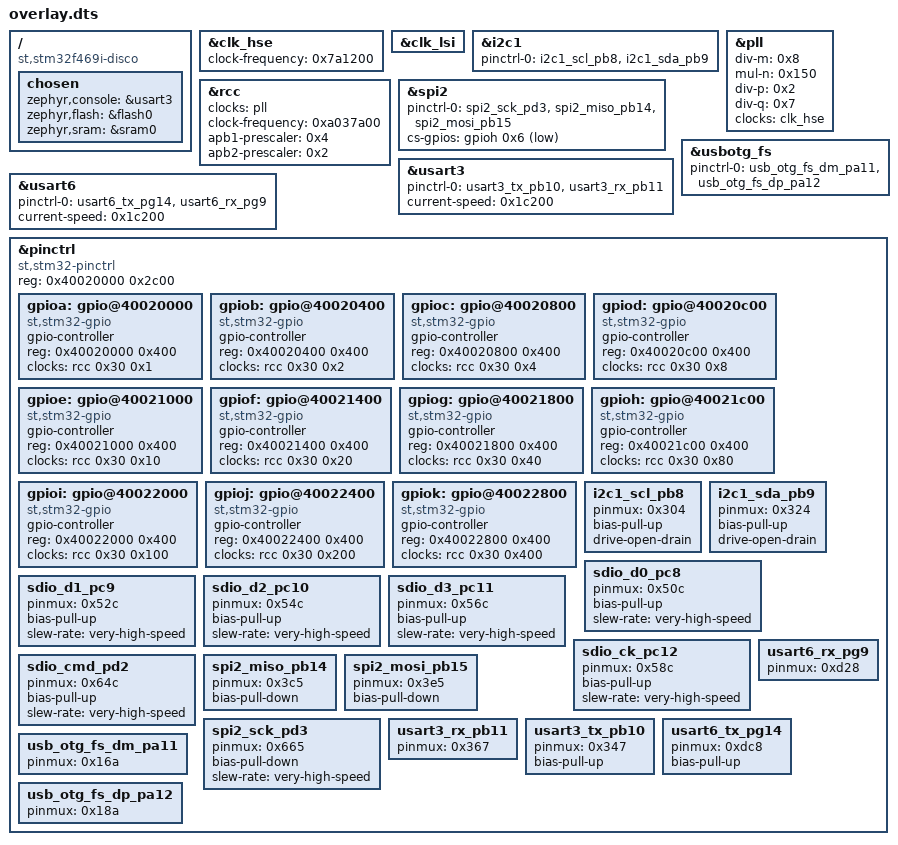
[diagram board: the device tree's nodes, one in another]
/ {
	compatible = "st,stm32f469i-disco";
	chosen {
		zephyr,console = &usart3;
		zephyr,flash = &flash0;
		zephyr,sram = &sram0;
	};
};
&clk_hse{
	status = "okay";
	clock-frequency = < 0x7a1200 >;
};
&clk_lsi{
	status = "okay";
};
&i2c1{
	status = "okay";
	pinctrl-0 = < &i2c1_scl_pb8 &i2c1_sda_pb9 >;
	pinctrl-names = "default";
};
&pll{
	status = "okay";
	div-m = < 0x8 >;
	mul-n = < 0x150 >;
	div-p = < 0x2 >;
	div-q = < 0x7 >;
	clocks = < &clk_hse >;
};
&rcc{
	clocks = < &pll >;
	clock-frequency = < 0xa037a00 >;
	apb1-prescaler = < 0x4 >;
	apb2-prescaler = < 0x2 >;
};
&spi2{
	status = "okay";
	pinctrl-0 = < &spi2_sck_pd3 &spi2_miso_pb14 &spi2_mosi_pb15 >;
	pinctrl-names = "default";
	cs-gpios = < &gpioh 0x6 0x11 >;
};
&usart3{
	status = "okay";
	pinctrl-0 = < &usart3_tx_pb10 &usart3_rx_pb11 >;
	pinctrl-names = "default";
	current-speed = < 0x1c200 >;
};
&usart6{
	status = "okay";
	pinctrl-0 = < &usart6_tx_pg14 &usart6_rx_pg9 >;
	pinctrl-names = "default";
	current-speed = < 0x1c200 >;
};
&usbotg_fs{
	status = "okay";
	pinctrl-0 = < &usb_otg_fs_dm_pa11 &usb_otg_fs_dp_pa12 >;
	pinctrl-names = "default";
};
&pinctrl{
	compatible = "st,stm32-pinctrl";
	#address-cells = < 0x1 >;
	#size-cells = < 0x1 >;
	reg = < 0x40020000 0x2c00 >;
	gpioa: gpio@40020000 {
		compatible = "st,stm32-gpio";
		gpio-controller;
		#gpio-cells = < 0x2 >;
		reg = < 0x40020000 0x400 >;
		clocks = < &rcc 0x30 0x1 >;
	};
	gpiob: gpio@40020400 {
		compatible = "st,stm32-gpio";
		gpio-controller;
		#gpio-cells = < 0x2 >;
		reg = < 0x40020400 0x400 >;
		clocks = < &rcc 0x30 0x2 >;
	};
	gpioc: gpio@40020800 {
		compatible = "st,stm32-gpio";
		gpio-controller;
		#gpio-cells = < 0x2 >;
		reg = < 0x40020800 0x400 >;
		clocks = < &rcc 0x30 0x4 >;
	};
	gpiod: gpio@40020c00 {
		compatible = "st,stm32-gpio";
		gpio-controller;
		#gpio-cells = < 0x2 >;
		reg = < 0x40020c00 0x400 >;
		clocks = < &rcc 0x30 0x8 >;
	};
	gpioe: gpio@40021000 {
		compatible = "st,stm32-gpio";
		gpio-controller;
		#gpio-cells = < 0x2 >;
		reg = < 0x40021000 0x400 >;
		clocks = < &rcc 0x30 0x10 >;
	};
	gpiof: gpio@40021400 {
		compatible = "st,stm32-gpio";
		gpio-controller;
		#gpio-cells = < 0x2 >;
		reg = < 0x40021400 0x400 >;
		clocks = < &rcc 0x30 0x20 >;
	};
	gpiog: gpio@40021800 {
		compatible = "st,stm32-gpio";
		gpio-controller;
		#gpio-cells = < 0x2 >;
		reg = < 0x40021800 0x400 >;
		clocks = < &rcc 0x30 0x40 >;
	};
	gpioh: gpio@40021c00 {
		compatible = "st,stm32-gpio";
		gpio-controller;
		#gpio-cells = < 0x2 >;
		reg = < 0x40021c00 0x400 >;
		clocks = < &rcc 0x30 0x80 >;
	};
	gpioi: gpio@40022000 {
		compatible = "st,stm32-gpio";
		gpio-controller;
		#gpio-cells = < 0x2 >;
		reg = < 0x40022000 0x400 >;
		clocks = < &rcc 0x30 0x100 >;
	};
	gpioj: gpio@40022400 {
		compatible = "st,stm32-gpio";
		gpio-controller;
		#gpio-cells = < 0x2 >;
		reg = < 0x40022400 0x400 >;
		clocks = < &rcc 0x30 0x200 >;
	};
	gpiok: gpio@40022800 {
		compatible = "st,stm32-gpio";
		gpio-controller;
		#gpio-cells = < 0x2 >;
		reg = < 0x40022800 0x400 >;
		clocks = < &rcc 0x30 0x400 >;
	};
	i2c1_scl_pb8: i2c1_scl_pb8 {
		pinmux = < 0x304 >;
		bias-pull-up;
		drive-open-drain;
	};
	i2c1_sda_pb9: i2c1_sda_pb9 {
		pinmux = < 0x324 >;
		bias-pull-up;
		drive-open-drain;
	};
	sdio_d0_pc8: sdio_d0_pc8 {
		pinmux = < 0x50c >;
		bias-pull-up;
		slew-rate = "very-high-speed";
	};
	sdio_d1_pc9: sdio_d1_pc9 {
		pinmux = < 0x52c >;
		bias-pull-up;
		slew-rate = "very-high-speed";
	};
	sdio_d2_pc10: sdio_d2_pc10 {
		pinmux = < 0x54c >;
		bias-pull-up;
		slew-rate = "very-high-speed";
	};
	sdio_d3_pc11: sdio_d3_pc11 {
		pinmux = < 0x56c >;
		bias-pull-up;
		slew-rate = "very-high-speed";
	};
	sdio_ck_pc12: sdio_ck_pc12 {
		pinmux = < 0x58c >;
		bias-pull-up;
		slew-rate = "very-high-speed";
	};
	sdio_cmd_pd2: sdio_cmd_pd2 {
		pinmux = < 0x64c >;
		bias-pull-up;
		slew-rate = "very-high-speed";
	};
	spi2_miso_pb14: spi2_miso_pb14 {
		pinmux = < 0x3c5 >;
		bias-pull-down;
	};
	spi2_mosi_pb15: spi2_mosi_pb15 {
		pinmux = < 0x3e5 >;
		bias-pull-down;
	};
	spi2_sck_pd3: spi2_sck_pd3 {
		pinmux = < 0x665 >;
		bias-pull-down;
		slew-rate = "very-high-speed";
	};
	usart3_rx_pb11: usart3_rx_pb11 {
		pinmux = < 0x367 >;
	};
	usart6_rx_pg9: usart6_rx_pg9 {
		pinmux = < 0xd28 >;
	};
	usart3_tx_pb10: usart3_tx_pb10 {
		pinmux = < 0x347 >;
		bias-pull-up;
	};
	usart6_tx_pg14: usart6_tx_pg14 {
		pinmux = < 0xdc8 >;
		bias-pull-up;
	};
	usb_otg_fs_dm_pa11: usb_otg_fs_dm_pa11 {
		pinmux = < 0x16a >;
	};
	usb_otg_fs_dp_pa12: usb_otg_fs_dp_pa12 {
		pinmux = < 0x18a >;
	};
};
